# APM32F00x register map
File version: 1.0
CPU: CM0+ r0p1, little endian, no MPU, no FPU, 4 interrupt priority bits
Registers are 32-bit, read-write, reset 0x0 unless marked. A register's access mark holds for its fields unless they carry their own. Offsets are from the block's base; [hi:lo] are bit positions; {n}, {i} and the like mark numbered series.

## TMR2 — 16-bit timer
Base 0x40003C00
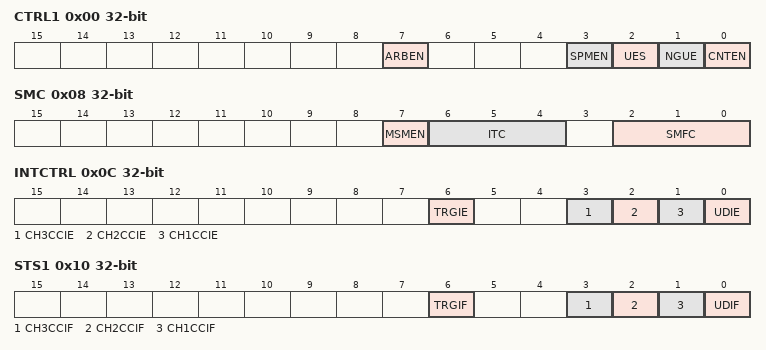
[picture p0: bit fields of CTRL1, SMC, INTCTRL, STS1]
0x00 CTRL1 — control register 1
  [7] ARBEN — Auto-Reload Preload Enable mask.
  [3] SPMEN — One Pulse Mode mask.
  [2] UES — Update Request Source mask.
  [1] NGUE — Update DIsable mask.
  [0] CNTEN — Counter Enable mask.
0x04 CTRL2 — control register 2
  [6:4] MMFC — Capture/Compare Preloaded Control mask.
0x08 SMC — Synchro mode control register
  [7] MSMEN — Slave Mode Selection mask.
  [6:4] ITC — Trigger Selection mask.
  [2:0] SMFC — Master/Slave Mode mask.
0x0C INTCTRL — interrupt enable register
  [6] TRGIE — Trigger Interrupt Enable mask.
  [3] CH3CCIE — Capture/Compare 3 Interrupt Enable mask.
  [2] CH2CCIE — Capture/Compare 2 Interrupt Enable mask.
  [1] CH1CCIE — Capture/Compare 1 Interrupt Enable mask.
  [0] UDIE — Update Interrupt Enable mask.
0x10 STS1 — status register 1
  [6] TRGIF — Trigger Interrupt Flag mask.
  [3] CH3CCIF — Capture/Compare 3 Interrupt Flag mask.
  [2] CH2CCIF — Capture/Compare 2 Interrupt Flag mask.
  [1] CH1CCIF — Capture/Compare 1 Interrupt Flag mask.
  [0] UDIF — Update Interrupt Flag mask.
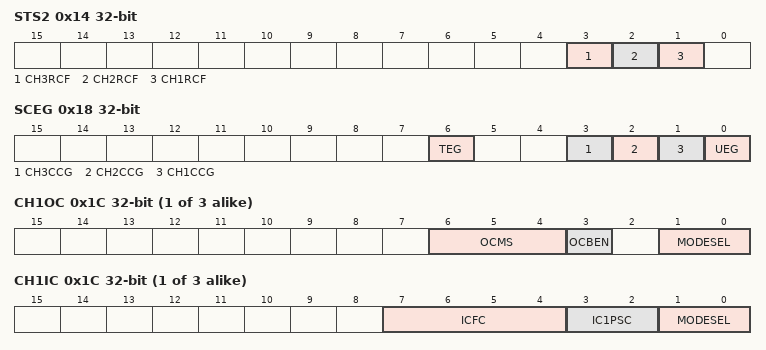
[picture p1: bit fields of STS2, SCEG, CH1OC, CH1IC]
0x14 STS2 — status register 2
  [3] CH3RCF — Capture/Compare 3 Overcapture Flag mask.
  [2] CH2RCF — Capture/Compare 2 Overcapture Flag mask.
  [1] CH1RCF — Capture/Compare 1 Overcapture Flag mask.
0x18 SCEG write — event generation register
  [6] TEG — Trigger Generation mask.
  [3] CH3CCG — Capture/Compare 3 Generation mask.
  [2] CH2CCG — Capture/Compare 2 Generation mask.
  [1] CH1CCG — Capture/Compare 1 Generation mask.
  [0] UEG — Update Generation mask.
{0x18+4i} CH{i}OC (i=1..3) — capture/compare mode register {i} (output mode)
  [6:4] OCMS — Output Compare {i} Mode mask.
  [3] OCBEN — Output Compare {i} Preload Enable mask.
  [1:0] MODESEL — Capture/Compare {i} Selection mask.
{0x18+4i} CH{i}IC (alternate view of CH{i}OC) (i=1..3) — capture/compare mode register {i} (input mode)
  [7:4] ICFC — Input capture {i} filter
  [3:2] IC{i}PSC — Input capture {i} prescaler
  [1:0] MODESEL — Capture/Compare {i} Selection mask.
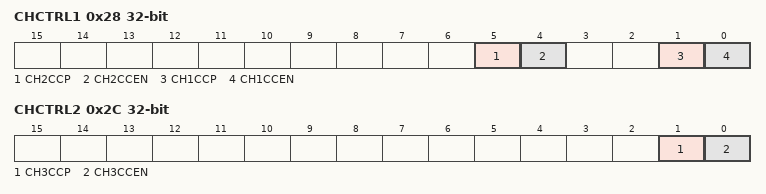
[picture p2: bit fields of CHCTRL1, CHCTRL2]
0x28 CHCTRL1 — Channel control register 1
  [5] CH2CCP — Capture/Compare 2 output Polarity mask.
  [4] CH2CCEN — Capture/Compare 2 output enable mask.
  [1] CH1CCP — Capture/Compare 1 output Polarity mask.
  [0] CH1CCEN — Capture/Compare 1 output enable mask.
0x2C CHCTRL2 — Channel control register 2
  [1] CH3CCP — Capture/Compare 3 output Polarity mask.
  [0] CH3CCEN — Capture/Compare 3 output enable mask.
0x30 CNT1 — Count register 1
  [7:0] CNT — Counter Value (MSB) mask.
0x34 CNT0 — Count register 0
  [7:0] CNT — Counter Value (LSB) mask.
0x38 PSC — divider register
  [3:0] PSC — Prescaler Value mask.
0x3C AUTORLD1 — Auto reload register 1
  [7:0] AUTORLD — Autoreload Value (MSB) mask.
0x40 AUTORLD0 — Auto reload register 0
  [7:0] AUTORLD — Autoreload Value (LSB) mask.
{0x3C+8i} CH{i}CC1 (i=1..3) — channel {i} compare/capture register 1
  [7:0] CC — Capture/Compare {i} Value (MSB) mask.
{0x40+8i} CH{i}CC0 (i=1..3) — channel {i} compare/capture register 0
  [7:0] CC — Capture/Compare {i} Value (LSB) mask.

## TMR4 — 8-bit timer
Base 0x40004000
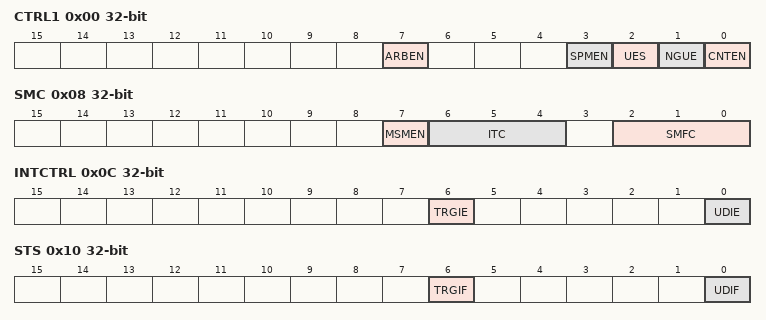
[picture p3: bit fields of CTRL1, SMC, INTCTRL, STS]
0x00 CTRL1 — control register 1
  [7] ARBEN — Auto-Reload Preload Enable mask.
  [3] SPMEN — One Pulse Mode mask.
  [2] UES — Update Request Source mask.
  [1] NGUE — Update DIsable mask.
  [0] CNTEN — Counter Enable mask.
0x04 CTRL2 — control register 2
  [6:4] MMFC — Capture/Compare Preloaded Control mask.
0x08 SMC — Synchro mode control register
  [7] MSMEN — Slave Mode Selection mask.
  [6:4] ITC — Trigger Selection mask.
  [2:0] SMFC — Master/Slave Mode mask.
0x0C INTCTRL — interrupt enable register
  [6] TRGIE — Trigger Interrupt Enable mask.
  [0] UDIE — Update Interrupt Enable mask.
0x10 STS write — status register 1
  [6] TRGIF — Trigger Interrupt Flag mask.
  [0] UDIF — Update Interrupt Flag mask.
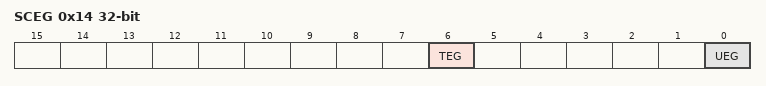
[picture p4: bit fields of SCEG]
0x14 SCEG write — event generation register
  [6] TEG — Trigger Generation mask.
  [0] UEG — Update Generation mask.
0x18 CNT — counter
  [7:0] CNT — Counter Value mask.
0x1C PSC — divider register
  [2:0] PSC — Prescaler Value mask.
0x20 AUTORLD — auto-reload register
  [7:0] RELOAD — Autoreload Value mask.
